# RTS5921 register map
Vendor: Realtek Semiconductor Corp.; Series: RTS5921 Series; File version: 0.01
CPU: ARMV8MBL r0p0, little endian, MPU, no FPU, VTOR, 3 interrupt priority bits
Registers are 32-bit, read-write, reset 0x0 unless marked. A register's access mark holds for its fields unless they carry their own. Offsets are from the block's base; [hi:lo] are bit positions.

## INTR_SPIC — Realtek RXI-312 SPI Controller
Base 0x40000000
Same registers: EXTR_SPIC 0x40001000
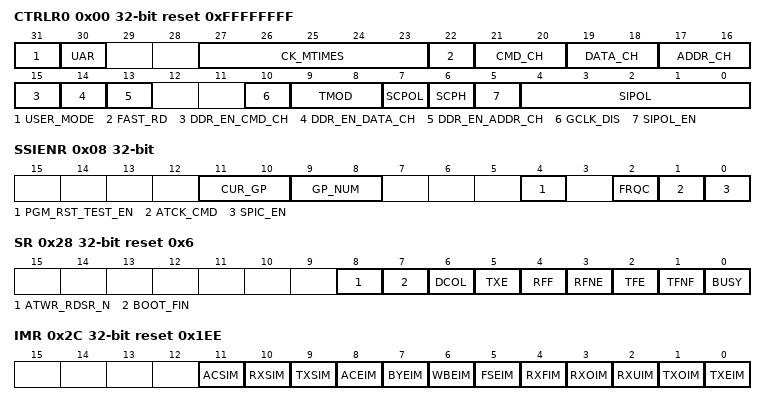
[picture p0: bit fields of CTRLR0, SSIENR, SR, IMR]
0x00 CTRLR0 reset 0xFFFFFFFF — Control Register 0
  [31] USER_MODE — User mode bit.
  [30] UAR — User mode bit auto reset. Enable to auto reset USER_MODE to 0 after user mode transaction is over.
  [27:23] CK_MTIMES — Indicate the auto-check times
  [22] FAST_RD — Enable use of fast read command in user mode. Use FBAUDR as spi_sclk when set.
  [21:20] CMD_CH — Channel number of command phase. 0: single, 1: dual, 2: quad, 3: octal.
  [19:18] DATA_CH — Channel number of data phase. 0: single, 1: dual, 2: quad, 3: octal.
  [17:16] ADDR_CH — Channel number for address phase. 0: single, 1: dual, 2: quad, 3: octal.
  [15] DDR_EN_CMD_CH — Enable DDR mode on CMD_CH (2-Byte CMD type). Only if DDR_EN defined.
  [14] DDR_EN_DATA_CH — Enable DDR mode on DATA_CH. Only if DDR_EN defined.
  [13] DDR_EN_ADDR_CH — Enable DDR mode on ADDR_CH. Only if DDR_EN defined.
  [10] GCLK_DIS — Disable gated clock of icg cell.
  [9:8] TMOD — Transfer mode. 00: transmit mode, others: receive mode.
  [7] SCPOL — Serial clock polarity. 0: inactive state is low, 1: inactive state is high.
  [6] SCPH — Serial clock phase. 0: toggles in middle of 1st data bit, 1: toggles at start of 1st data bit.
  [5] SIPOL_EN — Enable SIPOL control for SPI in/out signal polarity.
  [4:0] SIPOL — SPI input signal polarity
0x04 RX_NDF — Control Register 1
  [24:0] NDF — Indicates the number of data frames
0x08 SSIENR — SPIC Enable Register
  [11:10] CUR_GP ro — Current group, for frequency change .
  [9:8] GP_NUM — Target group, for frequency change.
  [4] PGM_RST_TEST_EN wo — Pulse warm reset. Test only.
  [2] FRQC — Enable/complete frequency change.
  [1] ATCK_CMD — Enable auto check command.
  [0] SPIC_EN — Enable SPIC / user mode transaction.
0x10 SER — Slave Enable Register
0x14 BAUDR reset 0xFFFFFFFF — Baud Rate Select
  [11:0] SCKDV — Define spi_sclk divider value. The frequency of spi_sclk is derived from: Frequency of spi_sclk = Frequency of bus_clk / (2*SCKDV).
0x18 TXFTLR — Transmit FIFO Threshold level
  [4:0] TFT — Transmit FIFO threshold.
0x1C RXFTLR reset 0xFFFFFFFF — Receive FIFO Threshold level
  [4:0] RFT — Receive FIFO threshold.
0x20 TXFLR — Transmit FIFO level Register
  [5:0] TXFLR ro — Indicates the FIFO level of valid data during transmission.
0x24 RXFLR — Receive FIFO level Register
  [5:0] RXFLR ro — Indicates the FIFO level of valid data during reception.
0x28 SR ro reset 0x6 — Status Register
  [8] ATWR_RDSR_N — The previous auto write cmd didn't check the status register (RDSR).
  [7] BOOT_FIN — Boot Finish status indicator.
  [6] DCOL — Data collision or transmitting status.
  [5] TXE — Transmission error indicator.
  [4] RFF — Receive FIFO full status.
  [3] RFNE — Receive FIFO not empty status.
  [2] TFE — Transmit FIFO empty status.
  [1] TFNF — Transmit FIFO not full status.
  [0] BUSY — SPIC busy flag.
0x2C IMR reset 0x1EE — Interrupt Mask Register
  [11] ACSIM — Auto-check Flash Status raw interrupt mask.
  [10] RXSIM — Transmit split interrupt mask.
  [9] TXSIM — Transmit split interrupt mask.
  [8] ACEIM — Auto-check timeout error interrupt mask.
  [7] BYEIM — Byte-Enable error interrupt mask.
  [6] WBEIM — Write burst error interrupt mask.
  [5] FSEIM — FIFO size error interrupt mask.
  [4] RXFIM — Receive FIFO full interrupt mask.
  [3] RXOIM — Receive FIFO overflow interrupt mask.
  [2] RXUIM — Receive FIFO underflow interrupt mask.
  [1] TXOIM — Transmit FIFO overflow interrupt mask.
  [0] TXEIM — Transmit FIFO empty interrupt mask.
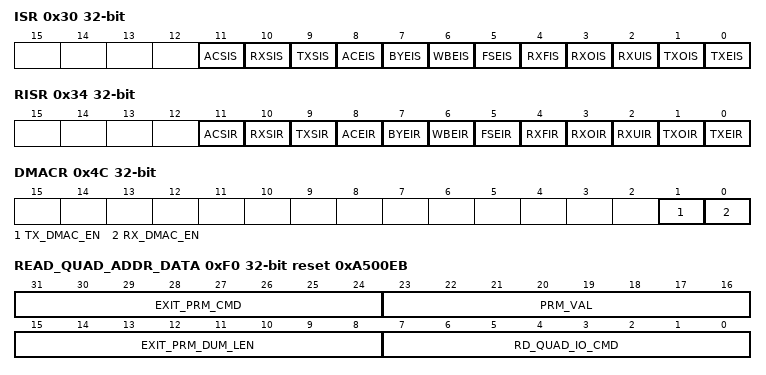
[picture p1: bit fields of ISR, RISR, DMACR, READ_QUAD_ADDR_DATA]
0x30 ISR ro — Interrupt Status Register
  [11] ACSIS — Auto-check Flash Status after masking. 1: spi_aceir_r is active after masking. 0: spi_aceir_r is not active after masking.
  [10] RXSIS — Receive split interrupt status after masking. 1: spi_rxsir_r is active after masking. 0: spi_rxsir_r is not active after masking.
  [9] TXSIS — Transmit split interrupt status after masking. 1: spi_txsir_r is active after masking. 0: spi_txsir_r is not active after masking.
  [8] ACEIS — Auto-check timeout error status after masking. 1: spi_aceir_r is active after masking. 0: spi_aceir_r is not active after masking.
  [7] BYEIS — Byte-Enable error interrupts status after masking. 1: spi_byeir_r is active after masking. 0: spi_byeir_r is not active after masking.
  [6] WBEIS — Write burst error interrupt status after masking. 1: spi_wbeir_r is active after masking. 0: spi_wbeir_r is not active after masking.
  [5] FSEIS — FIFO size error interrupts status after masking. 1: spi_fesir_r is active after masking. 0: spi_fesir_r is not active after masking.
  [4] RXFIS — Receive FIFO full interrupt status after masking. 1: spi_rxfir is active after masking. 0: spi_rxfir is not active after masking.
  [3] RXOIS — Receive FIFO overflow interrupt status after masking. 1: spi_rxoir_r is active after masking. 0: spi_rxoir_r is not active after masking.
  [2] RXUIS — Receive FIFO underflow interrupt status after masking. 1: spi_rxuir_r is active after masking. 0: spi_rxuir_r is not active after masking.
  [1] TXOIS — Transmit FIFO overflow interrupt status after masking. 1: spi_txoir_r is active after masking. 0: spi_txoir_r is not active after masking.
  [0] TXEIS — Transmit FIFO empty interrupt status after masking. 1: spi_txeir is active after masking. 0: spi_txeir is not active after masking.
0x34 RISR ro — Raw Interrupt Status Register
  [11] ACSIR — Auto-check Flash Status raw interrupt status prior to masking. 1: spi_acsir_r is active prior to masking. 0: spi_acsir_r is not active prior to masking.
  [10] RXSIR — Receive split interrupt status prior to masking. 1: spi_rxsir_r is active prior to masking. 0: spi_rxsir_r is not active prior to masking.
  [9] TXSIR — Transmit split interrupt status prior to masking. 1: spi_txsir_r is active prior to masking. 0: spi_txsir_r is not active prior to masking.
  [8] ACEIR — Auto-check timeout error raw interrupt status prior to masking. 1: spi_aceir_r is active prior to masking. 0: spi_aceir_r is not active prior to masking.
  [7] BYEIR — The Byte-Enable error interrupt raw status prior to masking. 1: spi_byeir_r is active prior to masking. 0: spi_byeir_r is not active prior to masking.
  [6] WBEIR — Write burst error raw interrupt status prior to masking. 1: spi_wbeir_r is active prior to masking. 0: spi_wbeir_r is not active prior to masking.
  [5] FSEIR — FIFO size error raw interrupt status prior to masking. 1: spi_fseir_r is active prior to masking. 0: spi_fseir_r is not active prior to masking.
  [4] RXFIR — Receive FIFO full raw interrupt status prior to masking. 1: spi_rxfir is active prior to masking. 0: spi_rxfir is not active prior to masking.
  [3] RXOIR — Receive FIFO overflow raw interrupt status prior to masking. 1: spi_rxoir_r is active prior to masking. 0: spi_rxoir_r is not active prior to masking.
  [2] RXUIR — Receive FIFO underflow raw interrupt status prior to masking. 1: spi_rxuir_r is active prior to masking. 0: spi_rxuir_r is not active prior to masking.
  [1] TXOIR — Transmit FIFO overflow raw interrupt status prior to masking. 1: spi_txoir_r is active prior to masking. 0: spi_txoir_r is not active prior to masking.
  [0] TXEIR — Transmit FIFO empty raw interrupt status prior to masking. 1: spi_txeir is active prior to masking. 0: spi_txeir is not active prior to masking.
0x38 TXOICR wo — Transmit FIFO Overflow Interrupt Clear Register
0x3C RXOICR ro — Receive FIFO Overflow Interrupt Clear Register
0x40 RXUICR ro — Receive FIFO Underflow Interrupt Clear Register
0x44 MSTICR wo — Master error Interrupt Clear Register
0x48 ICR wo — Interrupt Clear Register
0x4C DMACR — DMA Control Register
  [1] TX_DMAC_EN — Transmit DMA Enable. Enables/disables the transmit FIFO DMA channel. 0 = Transmit DMA disabled, 1 = Transmit DMA enabled.
  [0] RX_DMAC_EN — Receive DMA Enable. Enables/disables the receive FIFO DMA channel. 0 = Receive DMA disabled, 1 = Receive DMA enabled.
0x50 DMATDLR — DMA Transmit Data Level Register
0x54 DMARDLR — DMA Receive Data Level Register
0x58 IDR ro — Identification Register
0x5C SPIC_VERSION ro — SPIC version ID Register
0x60 DR — DATA REGISTER
0x60 DR_BYTE (alternate view of DR) — DATA REGISTER IN BYTE
0x60 DR_HALF (alternate view of DR) — DATA REGISTER IN HALF WORD
0x60 DR_WORD (alternate view of DR) — DATA REGISTER IN WORD
0xA0 DM_DR — Data Mask Data Register
0xE0 READ_FAST_SINGLE reset 0xB0B — Fast Read Data Command of SPI Flash
0xE4 READ_DUAL_DATA reset 0x3B — Dual Output Read Command of SPI Flash
0xE8 READ_DUAL_ADDR_DATA reset 0xBB — Dual I/O Read Command of SPI Flash
0xEC READ_QUAD_DATA reset 0x6B — Quad Output Read Command of SPI Flash
0xF0 READ_QUAD_ADDR_DATA reset 0xA500EB — Quad I/O Read Command of SPI Flash
  [31:24] EXIT_PRM_CMD — Exit High Performance Read Mode command.
  [23:16] PRM_VAL — High Performance Read Mode Value.
  [15:8] EXIT_PRM_DUM_LEN — Extend the Exit PRM command if it is more than 1 byte. It uses bus_clk as reference. For example, in QPI mode (4-4-4), for FFFFFFFFh data cycle (4-byte data in 8 SPI cycles), EXIT_PRM_CMD sends 1 byte (2 SPI cycles), and EXIT_PRM_DUM_LEN extends 6 SPI cycles. (SPI cycles: 6 * (2 * baud_rate)).
  [7:0] RD_QUAD_IO_CMD — SPI Flash command value for quad address and data read command.
0xF4 WRITE_SINGLE reset 0x202 — Page Program Command of SPI Flash
0xF8 WRITE_DUAL_DATA reset 0xA2 — Dual Data Input Program Command of SPI Flash
0xFC WRITE_DUAL_ADDR_DATA — Dual Address and Data Output Read Command of SPI Flash
0x100 WRITE_QUAD_DATA reset 0x32 — Quad Data Input Program Command of SPI Flash
0x104 WRITE_QUAD_ADDR_DATA reset 0x38 — Quad Address and Data Output Read Command of SPI Flash
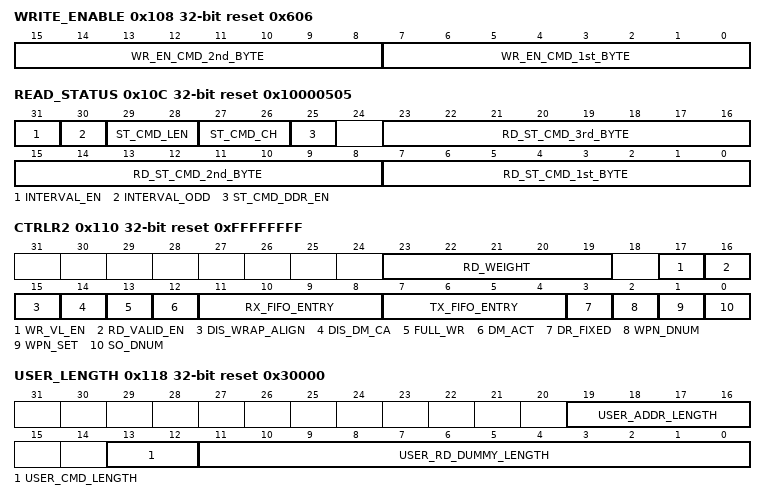
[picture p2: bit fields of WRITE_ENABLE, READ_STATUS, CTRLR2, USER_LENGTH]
0x108 WRITE_ENABLE reset 0x606 — Write Enable Command of SPI Flash
  [15:8] WR_EN_CMD_2nd_BYTE — SPI Flash command value of the 2nd byte of write enable. Available only if DDR_EN configuration is defined.
  [7:0] WR_EN_CMD_1st_BYTE — SPI Flash command value of the 1st byte of write enable.
0x10C READ_STATUS reset 0x10000505 — Read Status Command of SPI Flash
  [31] INTERVAL_EN — Enable INTERVAL_ODD (*).
  [30] INTERVAL_ODD — Odd/even byte check for 2-Byte status.
  [29:28] ST_CMD_LEN — Number of bytes in read status command .
  [27:26] ST_CMD_CH — Channel number for TX/RX in read status command.
  [25] ST_CMD_DDR_EN — DDR mode for ST_CMD_CH.
  [23:16] RD_ST_CMD_3rd_BYTE — Command value of 3rd byte for SPI Flash read status.
  [15:8] RD_ST_CMD_2nd_BYTE — Command value of 2nd byte for SPI Flash read status .
  [7:0] RD_ST_CMD_1st_BYTE — Command value of 1st byte for SPI Flash read status.
0x110 CTRLR2 reset 0xFFFFFFFF — Control Register 2
  [23:19] RD_WEIGHT — Read/Write priority.
  [17] WR_VL_EN — Enable variable write latency.
  [16] RD_VALID_EN — Enable variable read latency.
  [15] DIS_WRAP_ALIGN — Disable wrap_align in auto mode.
  [14] DIS_DM_CA — Disable spi_dm_oe_n for CMD and ADDR.
  [13] FULL_WR — Enable full write in auto mode.
  [12] DM_ACT — DM active polarity for specific PSRAM.
  [11:8] RX_FIFO_ENTRY — Valid RX FIFO entry index.
  [7:4] TX_FIFO_ENTRY — Valid TX FIFO/FIFO entry index.
  [3] DR_FIXED — AXI FIXED read mode on DR.
  [2] WPN_DNUM — WPn connects to spi_sout[2]/[3].
  [1] WPN_SET — Write protect setting.
  [0] SO_DNUM — SO connects to spi_sout[0]/[1].
0x114 FBAUDR reset 0x1 — Fast Baud Rate Select
0x118 USER_LENGTH reset 0x30000
  [19:16] USER_ADDR_LENGTH — Number of address phase bytes in user mode.
  [13:12] USER_CMD_LENGTH — Number of command bytes in user mode.
  [11:0] USER_RD_DUMMY_LENGTH — Delay cycles for receiving data in user mode.
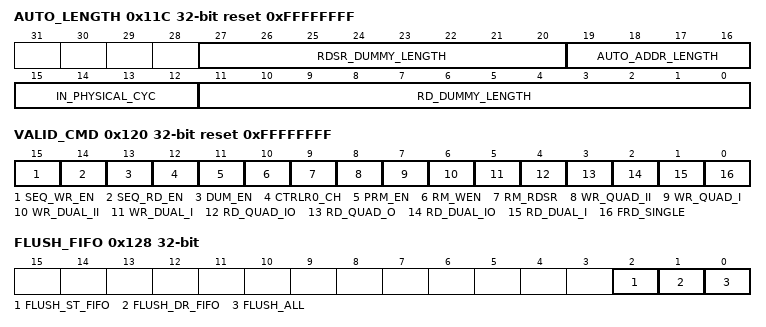
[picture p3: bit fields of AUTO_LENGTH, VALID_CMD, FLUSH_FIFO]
0x11C AUTO_LENGTH reset 0xFFFFFFFF — Auto Address Length Register
  [27:20] RDSR_DUMMY_LENGTH — Delay cycles for receiving data after RDSR command (referenced by bus_clk) Used in auto write or user mode with auto check.
  [19:16] AUTO_ADDR_LENGTH — Number of address phase bytes in auto read/write command (support 1~4 bytes). Set to 4 for 4-byte address mode in SPI Flash. * PRM in auto must set VALID_CMD[11] (PRM_EN) with correct AUTO_ADDR_LENGTH.
  [15:12] IN_PHYSICAL_CYC — Indicates number of SPIC CLK (bus_clk) cycles from pad to internal SPIC.
  [11:0] RD_DUMMY_LENGTH — Delay cycles for receiving data (referenced by bus_clk). * Don't include SPIC CLK (bus_clk) cycles from pad to internal SPIC.
0x120 VALID_CMD reset 0xFFFFFFFF — Valid Command Register
  [15] SEQ_WR_EN — Enable (1) sequential write in auto mode. Disabling deactivates spi_csn and this feature immediately. (Run after SPIC boot finish.)
  [14] SEQ_RD_EN — Enable (1) sequential read in auto mode. Disabling deactivates spi_csn and this feature immediately. (Run after SPIC boot finish.)
  [13] DUM_EN — Enable dummy byte (DUM_BYTE_VAL) after address in auto read. If PRM_EN active, push PRM_Value instead. If RD_DUMMY_LENGTH = 0, dummy byte will not be pushed.
  [12] CTRLR0_CH — Use CTRLR0 CMD_CH/DATA_CH/ADDR_CH and DDR_EN field in Auto mode. Otherwise, select by VALID_CMD. (Refer to datasheet for Flash mode usage.)
  [11] PRM_EN — Enable performance read mode in Auto Mode. Auto exit before auto write or enter user mode. (Refer to detailed flow in datasheet.)
  [10] RM_WEN — Remove write enable command in auto write.
  [9] RM_RDSR — Remove read status register in auto write.
  [8] WR_QUAD_II — Enable (1-4-4) quad addr/data write command valid for execution.
  [7] WR_QUAD_I — Enable (1-1-4) quad data write command valid for execution.
  [6] WR_DUAL_II — Enable (1-2-2) dual addr/data write command valid for execution.
  [5] WR_DUAL_I — Enable (1-1-2) dual data write command valid for execution.
  [4] RD_QUAD_IO — Enable (1-4-4) quad addr/data read command valid for execution.
  [3] RD_QUAD_O — Enable (1-1-4) quad data read command valid for execution.
  [2] RD_DUAL_IO — Enable (1-2-2) dual addr/data read command valid for execution.
  [1] RD_DUAL_I — Enable (1-1-2) dual data read command valid for execution.
  [0] FRD_SINGLE — Enable (1-1-1) fast read command valid for execution.
0x124 FLASH_SIZE
0x128 FLUSH_FIFO — Write to flush specific or all FIFOs. Commonly used when SPIC is not in normal operation or FIFO data is invalid.
  [2] FLUSH_ST_FIFO wo — Write 1 to clear all data in the ST_FIFO.
  [1] FLUSH_DR_FIFO wo — Write 1 to clear all data in the TX_FIFO and RX_FIFO.
  [0] FLUSH_ALL wo — Write 1 to clear all data in TX_FIFO, RX_FIFO, ST_FIFO and reset all FSMs.
0x12C DUM_BYTE — Dummy Byte Value
0x130 TX_NDF
0x134 DEVICE_INFO ro reset 0x118
0x138 TPR0 reset 0xFFFFFFFF — Timing Parameters
0x13C AUTO_LENGTH2 — Auto Address Length Register 2
0x140 TPR1 reset 0x1 — Timing Parameters Register 1
